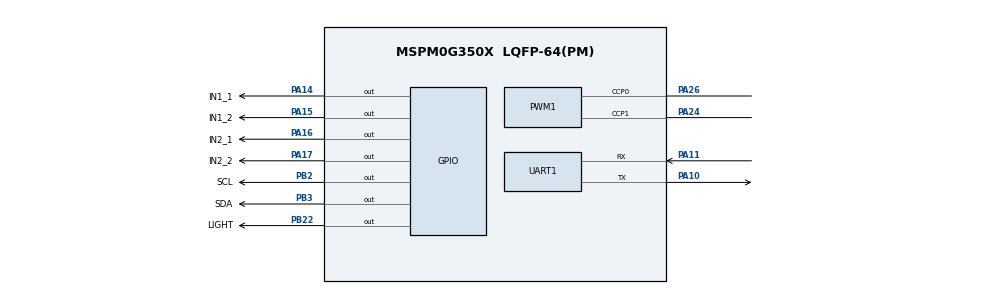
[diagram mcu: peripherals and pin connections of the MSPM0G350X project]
/**
 *
 * @cliArgs --device "MSPM0G350X" --part "Default" --package "LQFP-64(PM)" --product "mspm0_sdk@2.10.00.04"
 * @versions {"tool":"1.28.0+4712"}
 */

/**
 * Import the modules used in this configuration.
 */
const GPIO   = scripting.addModule("/ti/driverlib/GPIO", {}, false);
const GPIO1  = GPIO.addInstance();
const GPIO2  = GPIO.addInstance();
const GPIO3  = GPIO.addInstance();
const GPIO4  = GPIO.addInstance();
const GPIO5  = GPIO.addInstance();
const GPIO6  = GPIO.addInstance();
const GPIO7  = GPIO.addInstance();
const PWM    = scripting.addModule("/ti/driverlib/PWM", {}, false);
const PWM1   = PWM.addInstance();
const SYSCTL = scripting.addModule("/ti/driverlib/SYSCTL");
const UART   = scripting.addModule("/ti/driverlib/UART", {}, false);
const UART1  = UART.addInstance();

/**
 * Write custom configuration values to the imported modules.
 */
const divider2       = system.clockTree["HFCLK4MFPCLKDIV"];
divider2.divideValue = 10;

const divider9       = system.clockTree["UDIV"];
divider9.divideValue = 2;

const gate8  = system.clockTree["MFPCLKGATE"];
gate8.enable = true;

const mux4       = system.clockTree["EXHFMUX"];
mux4.inputSelect = "EXHFMUX_XTAL";

const mux8       = system.clockTree["HSCLKMUX"];
mux8.inputSelect = "HSCLKMUX_SYSPLL2X";

const mux10       = system.clockTree["MFPCLKMUX"];
mux10.inputSelect = "MFPCLKMUX_HFCLK";

const mux12       = system.clockTree["SYSPLLMUX"];
mux12.inputSelect = "zSYSPLLMUX_HFCLK";

const pinFunction4     = system.clockTree["HFXT"];
pinFunction4.enable    = true;
pinFunction4.inputFreq = 40;

GPIO1.$name                              = "OLED";
GPIO1.port                               = "PORTB";
GPIO1.portSegment                        = "Lower";
GPIO1.associatedPins.create(2);
GPIO1.associatedPins[0].$name            = "SCL";
GPIO1.associatedPins[0].initialValue     = "SET";
GPIO1.associatedPins[0].internalResistor = "PULL_UP";
GPIO1.associatedPins[0].assignedPin      = "2";
GPIO1.associatedPins[0].pin.$assign      = "PB2";
GPIO1.associatedPins[1].$name            = "SDA";
GPIO1.associatedPins[1].initialValue     = "SET";
GPIO1.associatedPins[1].internalResistor = "PULL_UP";
GPIO1.associatedPins[1].assignedPin      = "3";
GPIO1.associatedPins[1].pin.$assign      = "PB3";

const Board = scripting.addModule("/ti/driverlib/Board", {}, false);

GPIO2.$name                         = "LED";
GPIO2.port                          = "PORTB";
GPIO2.portSegment                   = "Upper";
GPIO2.associatedPins[0].$name       = "LIGHT";
GPIO2.associatedPins[0].assignedPin = "22";
GPIO2.associatedPins[0].pin.$assign = "PB22";

GPIO3.$name                              = "encode";
GPIO3.port                               = "PORTA";
GPIO3.portSegment                        = "Lower";
GPIO3.associatedPins.create(4);
GPIO3.associatedPins[0].direction        = "INPUT";
GPIO3.associatedPins[0].assignedPin      = "0";
GPIO3.associatedPins[0].interruptEn      = true;
GPIO3.associatedPins[0].internalResistor = "PULL_DOWN";
GPIO3.associatedPins[0].polarity         = "RISE";
GPIO3.associatedPins[0].$name            = "LEFT_A";
GPIO3.associatedPins[1].direction        = "INPUT";
GPIO3.associatedPins[1].assignedPin      = "1";
GPIO3.associatedPins[1].internalResistor = "PULL_DOWN";
GPIO3.associatedPins[1].$name            = "LEFT_B";
GPIO3.associatedPins[2].$name            = "RIGHT_A";
GPIO3.associatedPins[2].direction        = "INPUT";
GPIO3.associatedPins[2].interruptEn      = true;
GPIO3.associatedPins[2].polarity         = "RISE";
GPIO3.associatedPins[2].internalResistor = "PULL_DOWN";
GPIO3.associatedPins[2].assignedPin      = "8";
GPIO3.associatedPins[3].$name            = "RIGHT_B";
GPIO3.associatedPins[3].assignedPin      = "9";
GPIO3.associatedPins[3].direction        = "INPUT";
GPIO3.associatedPins[3].internalResistor = "PULL_DOWN";

GPIO4.$name                              = "WHEEL_CTRL";
GPIO4.port                               = "PORTA";
GPIO4.associatedPins.create(4);
GPIO4.associatedPins[0].$name            = "IN1_1";
GPIO4.associatedPins[0].internalResistor = "PULL_DOWN";
GPIO4.associatedPins[0].assignedPin      = "14";
GPIO4.associatedPins[0].pin.$assign      = "PA14";
GPIO4.associatedPins[1].$name            = "IN1_2";
GPIO4.associatedPins[1].internalResistor = "PULL_DOWN";
GPIO4.associatedPins[1].assignedPin      = "15";
GPIO4.associatedPins[1].pin.$assign      = "PA15";
GPIO4.associatedPins[2].$name            = "IN2_1";
GPIO4.associatedPins[2].internalResistor = "PULL_DOWN";
GPIO4.associatedPins[2].assignedPin      = "16";
GPIO4.associatedPins[2].pin.$assign      = "PA16";
GPIO4.associatedPins[3].$name            = "IN2_2";
GPIO4.associatedPins[3].internalResistor = "PULL_DOWN";
GPIO4.associatedPins[3].assignedPin      = "17";
GPIO4.associatedPins[3].pin.$assign      = "PA17";

GPIO5.$name                                 = "IR_SENSOR";
GPIO5.associatedPins.create(8);
GPIO5.associatedPins[0].$name               = "IR1";
GPIO5.associatedPins[0].direction           = "INPUT";
GPIO5.associatedPins[0].internalResistor    = "PULL_UP";
GPIO5.associatedPins[0].assignedPort        = "PORTA";
GPIO5.associatedPins[0].assignedPortSegment = "Upper";
GPIO5.associatedPins[0].assignedPin         = "28";
GPIO5.associatedPins[1].$name               = "IR2";
GPIO5.associatedPins[1].direction           = "INPUT";
GPIO5.associatedPins[1].internalResistor    = "PULL_UP";
GPIO5.associatedPins[1].assignedPort        = "PORTA";
GPIO5.associatedPins[1].assignedPin         = "31";
GPIO5.associatedPins[2].$name               = "IR3";
GPIO5.associatedPins[2].internalResistor    = "PULL_UP";
GPIO5.associatedPins[2].assignedPort        = "PORTB";
GPIO5.associatedPins[2].assignedPin         = "4";
GPIO5.associatedPins[2].direction           = "INPUT";
GPIO5.associatedPins[3].$name               = "IR4";
GPIO5.associatedPins[3].direction           = "INPUT";
GPIO5.associatedPins[3].internalResistor    = "PULL_UP";
GPIO5.associatedPins[3].assignedPort        = "PORTB";
GPIO5.associatedPins[3].assignedPin         = "5";
GPIO5.associatedPins[4].$name               = "IR5";
GPIO5.associatedPins[4].direction           = "INPUT";
GPIO5.associatedPins[4].internalResistor    = "PULL_UP";
GPIO5.associatedPins[4].assignedPin         = "0";
GPIO5.associatedPins[5].$name               = "IR6";
GPIO5.associatedPins[5].direction           = "INPUT";
GPIO5.associatedPins[5].assignedPin         = "11";
GPIO5.associatedPins[5].internalResistor    = "PULL_UP";
GPIO5.associatedPins[6].$name               = "IR7";
GPIO5.associatedPins[6].direction           = "INPUT";
GPIO5.associatedPins[6].internalResistor    = "PULL_UP";
GPIO5.associatedPins[6].assignedPort        = "PORTB";
GPIO5.associatedPins[6].assignedPin         = "12";
GPIO5.associatedPins[7].$name               = "IR8";
GPIO5.associatedPins[7].direction           = "INPUT";
GPIO5.associatedPins[7].internalResistor    = "PULL_UP";
GPIO5.associatedPins[7].assignedPort        = "PORTB";
GPIO5.associatedPins[7].assignedPin         = "13";

GPIO6.$name                              = "KEY";
GPIO6.associatedPins.create(3);
GPIO6.associatedPins[0].$name            = "UP";
GPIO6.associatedPins[0].direction        = "INPUT";
GPIO6.associatedPins[0].internalResistor = "PULL_UP";
GPIO6.associatedPins[0].assignedPort     = "PORTB";
GPIO6.associatedPins[0].assignedPin      = "8";
GPIO6.associatedPins[1].$name            = "DOWN";
GPIO6.associatedPins[1].direction        = "INPUT";
GPIO6.associatedPins[1].internalResistor = "PULL_UP";
GPIO6.associatedPins[1].assignedPin      = "7";
GPIO6.associatedPins[1].assignedPort     = "PORTB";
GPIO6.associatedPins[2].$name            = "ENTER";
GPIO6.associatedPins[2].direction        = "INPUT";
GPIO6.associatedPins[2].internalResistor = "PULL_UP";
GPIO6.associatedPins[2].assignedPort     = "PORTB";
GPIO6.associatedPins[2].assignedPin      = "6";

GPIO7.$name                              = "W25Q64";
GPIO7.associatedPins.create(4);
GPIO7.associatedPins[0].$name            = "cs";
GPIO7.associatedPins[0].initialValue     = "SET";
GPIO7.associatedPins[0].assignedPort     = "PORTA";
GPIO7.associatedPins[0].assignedPin      = "27";
GPIO7.associatedPins[0].internalResistor = "PULL_UP";
GPIO7.associatedPins[1].$name            = "do";
GPIO7.associatedPins[1].direction        = "INPUT";
GPIO7.associatedPins[1].assignedPort     = "PORTA";
GPIO7.associatedPins[1].assignedPin      = "25";
GPIO7.associatedPins[1].internalResistor = "PULL_UP";
GPIO7.associatedPins[2].$name            = "clk";
GPIO7.associatedPins[2].assignedPort     = "PORTB";
GPIO7.associatedPins[2].assignedPin      = "25";
GPIO7.associatedPins[2].internalResistor = "PULL_UP";
GPIO7.associatedPins[3].$name            = "di";
GPIO7.associatedPins[3].assignedPort     = "PORTB";
GPIO7.associatedPins[3].assignedPin      = "20";
GPIO7.associatedPins[3].internalResistor = "PULL_UP";

PWM1.$name                              = "WHEEL";
PWM1.clockDivider                       = 8;
PWM1.timerCount                         = 1001;
PWM1.peripheral.ccp0Pin.$assign         = "PA26";
PWM1.peripheral.ccp1Pin.$assign         = "PA24";
PWM1.PWM_CHANNEL_0.$name                = "ti_driverlib_pwm_PWMTimerCC0";
PWM1.PWM_CHANNEL_1.$name                = "ti_driverlib_pwm_PWMTimerCC1";
PWM1.ccp0PinConfig.$name                = "ti_driverlib_gpio_GPIOPinGeneric0";
PWM1.ccp0PinConfig.direction            = scripting.forceWrite("OUTPUT");
PWM1.ccp0PinConfig.hideOutputInversion  = scripting.forceWrite(false);
PWM1.ccp0PinConfig.onlyInternalResistor = scripting.forceWrite(false);
PWM1.ccp0PinConfig.passedPeripheralType = scripting.forceWrite("Digital");
PWM1.ccp1PinConfig.$name                = "ti_driverlib_gpio_GPIOPinGeneric1";
PWM1.ccp1PinConfig.direction            = scripting.forceWrite("OUTPUT");
PWM1.ccp1PinConfig.hideOutputInversion  = scripting.forceWrite(false);
PWM1.ccp1PinConfig.onlyInternalResistor = scripting.forceWrite(false);
PWM1.ccp1PinConfig.passedPeripheralType = scripting.forceWrite("Digital");

SYSCTL.forceDefaultClkConfig = true;

UART1.uartClkDiv                       = "8";
UART1.$name                            = "UART0";
UART1.targetBaudRate                   = 115200;
UART1.peripheral.$assign               = "UART0";
UART1.peripheral.rxPin.$assign         = "PA11";
UART1.peripheral.txPin.$assign         = "PA10";
UART1.txPinConfig.$name                = "ti_driverlib_gpio_GPIOPinGeneric2";
UART1.txPinConfig.direction            = scripting.forceWrite("OUTPUT");
UART1.txPinConfig.hideOutputInversion  = scripting.forceWrite(false);
UART1.txPinConfig.onlyInternalResistor = scripting.forceWrite(false);
UART1.txPinConfig.passedPeripheralType = scripting.forceWrite("Digital");
UART1.txPinConfig.enableConfig         = true;
UART1.txPinConfig.internalResistor     = "PULL_UP";
UART1.rxPinConfig.$name                = "ti_driverlib_gpio_GPIOPinGeneric3";
UART1.rxPinConfig.hideOutputInversion  = scripting.forceWrite(false);
UART1.rxPinConfig.onlyInternalResistor = scripting.forceWrite(false);
UART1.rxPinConfig.passedPeripheralType = scripting.forceWrite("Digital");
UART1.rxPinConfig.enableConfig         = true;
UART1.rxPinConfig.internalResistor     = "PULL_UP";

/**
 * Pinmux solution for unlocked pins/peripherals. This ensures that minor changes to the automatic solver in a future
 * version of the tool will not impact the pinmux you originally saw.  These lines can be completely deleted in order to
 * re-solve from scratch.
 */
pinFunction4.peripheral.$suggestSolution           = "SYSCTL";
pinFunction4.peripheral.hfxInPin.$suggestSolution  = "PA5";
pinFunction4.peripheral.hfxOutPin.$suggestSolution = "PA6";
Board.peripheral.$suggestSolution                  = "DEBUGSS";
Board.peripheral.swclkPin.$suggestSolution         = "PA20";
Board.peripheral.swdioPin.$suggestSolution         = "PA19";
GPIO3.associatedPins[0].pin.$suggestSolution       = "PA0";
GPIO3.associatedPins[1].pin.$suggestSolution       = "PA1";
GPIO3.associatedPins[2].pin.$suggestSolution       = "PA8";
GPIO3.associatedPins[3].pin.$suggestSolution       = "PA9";
GPIO5.associatedPins[0].pin.$suggestSolution       = "PA28";
GPIO5.associatedPins[1].pin.$suggestSolution       = "PA31";
GPIO5.associatedPins[2].pin.$suggestSolution       = "PB4";
GPIO5.associatedPins[3].pin.$suggestSolution       = "PB5";
GPIO5.associatedPins[4].pin.$suggestSolution       = "PB0";
GPIO5.associatedPins[5].pin.$suggestSolution       = "PB11";
GPIO5.associatedPins[6].pin.$suggestSolution       = "PB12";
GPIO5.associatedPins[7].pin.$suggestSolution       = "PB13";
GPIO6.associatedPins[0].pin.$suggestSolution       = "PB8";
GPIO6.associatedPins[1].pin.$suggestSolution       = "PB7";
GPIO6.associatedPins[2].pin.$suggestSolution       = "PB6";
GPIO7.associatedPins[0].pin.$suggestSolution       = "PA27";
GPIO7.associatedPins[1].pin.$suggestSolution       = "PA25";
GPIO7.associatedPins[2].pin.$suggestSolution       = "PB25";
GPIO7.associatedPins[3].pin.$suggestSolution       = "PB20";
PWM1.peripheral.$suggestSolution                   = "TIMG7";
SYSCTL.peripheral.$suggestSolution                 = "SYSCTL";
